# APM32F00x register map
File version: 1.0
CPU: CM0+ r0p0, little endian, no MPU, no FPU, 4 interrupt priority bits
Registers are 32-bit, read-write, reset 0x0 unless marked. A register's access mark holds for its fields unless they carry their own. Offsets are from the block's base; [hi:lo] are bit positions; {n}, {i} and the like mark numbered series.

## TMR4 — 8-bit timer
Base 0x40004000
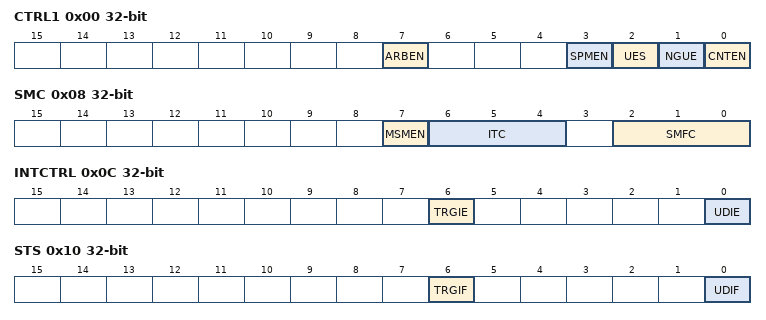
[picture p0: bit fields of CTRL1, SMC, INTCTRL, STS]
0x00 CTRL1 — control register 1
  [7] ARBEN — Auto-Reload Preload Enable mask.
  [3] SPMEN — One Pulse Mode mask.
  [2] UES — Update Request Source mask.
  [1] NGUE — Update DIsable mask.
  [0] CNTEN — Counter Enable mask.
0x04 CTRL2 — control register 2
  [6:4] MMFC — Capture/Compare Preloaded Control mask.
0x08 SMC — Synchro mode control register
  [7] MSMEN — Slave Mode Selection mask.
  [6:4] ITC — Trigger Selection mask.
  [2:0] SMFC — Master/Slave Mode mask.
0x0C INTCTRL — interrupt enable register
  [6] TRGIE — Trigger Interrupt Enable mask.
  [0] UDIE — Update Interrupt Enable mask.
0x10 STS write — status register 1
  [6] TRGIF — Trigger Interrupt Flag mask.
  [0] UDIF — Update Interrupt Flag mask.
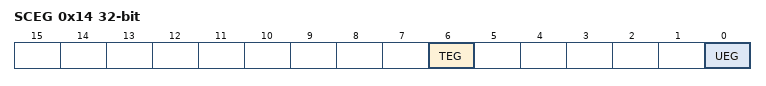
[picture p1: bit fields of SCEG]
0x14 SCEG write — event generation register
  [6] TEG — Trigger Generation mask.
  [0] UEG — Update Generation mask.
0x18 CNT — counter
  [7:0] CNT — Counter Value mask.
0x1C DIV — divider register
  [2:0] DIV — Prescaler Value mask.
0x20 AUTORLD — auto-reload register
  [7:0] RELOAD — Autoreload Value mask.

## SPI — Serial peripheral interface
Base 0x40002C00
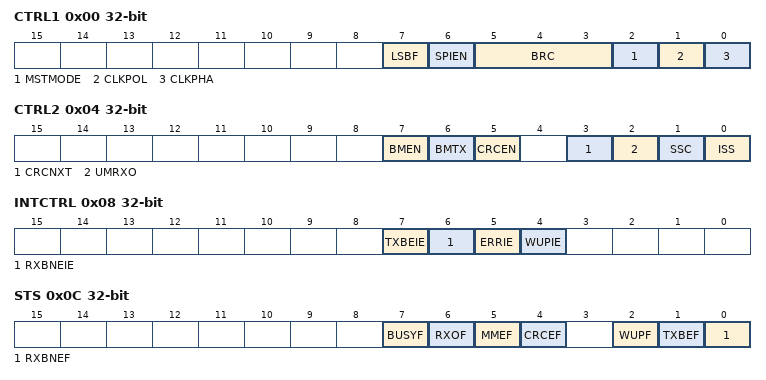
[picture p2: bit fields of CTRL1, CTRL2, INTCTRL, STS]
0x00 CTRL1 — Control register 1
  [7] LSBF, [6] SPIEN, [5:3] BRC, [2] MSTMODE, [1] CLKPOL, [0] CLKPHA
0x04 CTRL2 — Control register 2
  [7] BMEN, [6] BMTX, [5] CRCEN, [3] CRCNXT, [2] UMRXO, [1] SSC, [0] ISS
0x08 INTCTRL — Interrupt control register
  [7] TXBEIE, [6] RXBNEIE, [5] ERRIE, [4] WUPIE
0x0C STS — Status register
  [7] BUSYF, [6] RXOF, [5] MMEF, [4] CRCEF, [2] WUPF, [1] TXBEF, [0] RXBNEF
0x10 DATA
  [7:0] DATA
0x14 CRCPOLY — CRC polynomial register
  [7:0] polynomial
0x18 RXCRC ro
  [7:0] CRC
0x20 TXCRC ro
  [7:0] CRC

## ADC — Analog to digital converter
Base 0x40004400
{0x0+4i} DATABUF{i} ro (i=0..19) — Data buffer 0
  [7:0] DATABUF{i} — Regular data {i}
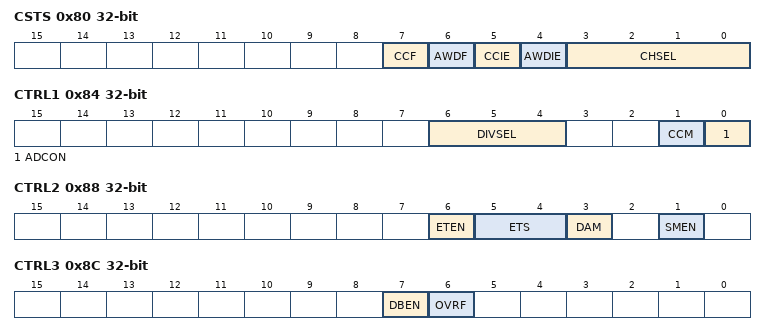
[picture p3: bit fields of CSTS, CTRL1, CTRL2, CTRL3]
0x80 CSTS — control/status register
  [7] CCF — Regular channel end of conversion
  [6] AWDF — Analog watchdog flag
  [5] CCIE
  [4] AWDIE
  [3:0] CHSEL
0x84 CTRL1 — control register 1
  [6:4] DIVSEL, [1] CCM, [0] ADCON
0x88 CTRL2 — control register 2
  [6] ETEN, [5:4] ETS, [3] DAM, [1] SMEN
0x8C CTRL3 — control register 3
  [7] DBEN, [6] OVRF
0x90 DATA1 ro — high-regular data register
  [7:0] DATA — Regular data
0x94 DATA0 ro — low-regular data register
  [7:0] DATA — Regular data
0x98 STD1 — Schmitt trigger disable register high
  [7:0] STD — Schmitt trigger prohibit high
0x9C STD0 — Schmitt trigger disable register low
  [7:0] STD — Schmitt trigger prohibit low
0xA0 AWDHT1 reset 0xFFF — watchdog higher threshold register high
  [7:0] THRESHOLD — Analog watchdog higher threshold high
0xA4 AWDHT0 reset 0x3 — watchdog higher threshold register low
  [7:0] THRESHOLD — Analog watchdog higher threshold low
0xA8 AWDLT1 — watchdog lower threshold register high
  [7:0] LT — Analog watchdog lower threshold high
0xAC AWDLT0 — watchdog lower threshold register low
  [7:0] THRESHOLD — Analog watchdog lower threshold low
0xB0 AWDS1 — Watchdog status high register
  [1:0] AWDS — Watchdog status register
0xB4 AWDS0 — Watchdog status low register
  [7:0] AWDS — Watchdog status register
0xB8 AWDEN1 — Watchdog Control high register
  [1:0] AWDEN — Watchdog Control egister
0xBC AWDEN0 — Watchdog Control low register
  [7:0] AWDEN — Watchdog Control egister
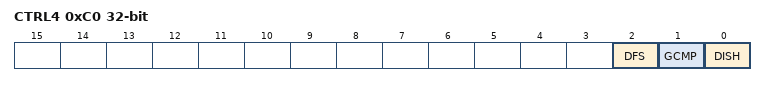
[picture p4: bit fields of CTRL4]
0xC0 CTRL4 — Control register 4
  [2] DFS, [1] GCMP, [0] DISH
0xC4 OFFSET
  [7:0] OFFSET

## EINT — External interrupt control
Base 0x40001800
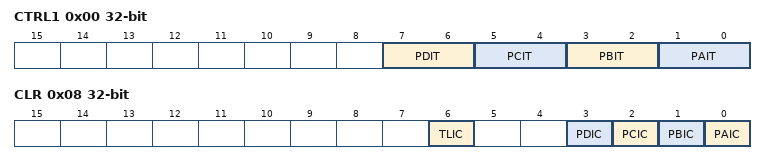
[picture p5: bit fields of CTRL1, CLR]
0x00 CTRL1 — External Interrupt Control Register for PORTA to PORTD
  [7:6] PDIT — PORTD external interrupt sensitivity bits mask
  [5:4] PCIT — PORTC external interrupt sensitivity bits mask
  [3:2] PBIT — PORTB external interrupt sensitivity bits mask
  [1:0] PAIT — PORTA external interrupt sensitivity bits mask
0x04 CTRL2 — External Interrupt Control Register for PORTE and TLI
  [2] TLIT
0x08 CLR write — External interrupt clear register
  [6] TLIC, [3] PDIC, [2] PCIC, [1] PBIC, [0] PAIC

## IWDT — Independent Watchdog
Base 0x40002000
0x00 KEYWORD wo — Key Register
  [7:0] KEY
0x04 DIV — Prescaler Register
  [2:0] DIV
0x08 CNTRLD write reset 0xFF — Reload Register
  [7:0] CNTRLD

## WWDT — Window Watchdog
Base 0x40001C00
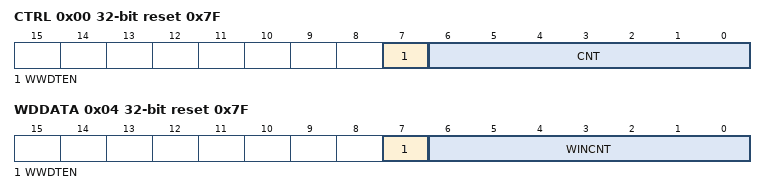
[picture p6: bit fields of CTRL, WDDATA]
0x00 CTRL reset 0x7F — Control Register
  [7] WWDTEN, [6:0] CNT
0x04 WDDATA reset 0x7F — Window Register
  [7] WWDTEN, [6:0] WINCNT

## BBEP — Beeper
Base 0x40002800
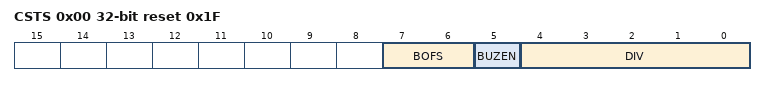
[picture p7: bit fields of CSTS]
0x00 CSTS reset 0x1F — External Interrupt Control Register for PORTA to PORTD
  [7:6] BOFS — Beeper frequency selection mask
  [5] BUZEN — Beeper enable mask
  [4:0] DIV — Beeper Divider prescalar mask

## WUPT — Auto wake up
Base 0x40002400
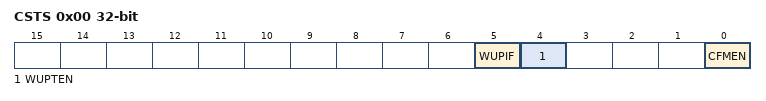
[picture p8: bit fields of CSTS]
0x00 CSTS — WUPT Control status register
  [5] WUPIF — Interrupt flag mask
  [4] WUPTEN — Auto Wake-up enable mask
  [0] CFMEN — LSI Measurement enable mask
0x04 DIV reset 0x3F — WUPT Asynchronous prescaler buffer
  [5:0] DIV — Asynchronous Prescaler divider mask
0x08 TBC write — WUPT Time base selection register
  [3:0] TBC — Timebase selection mask

## FMC — Flash Interface
Base 0x40011000
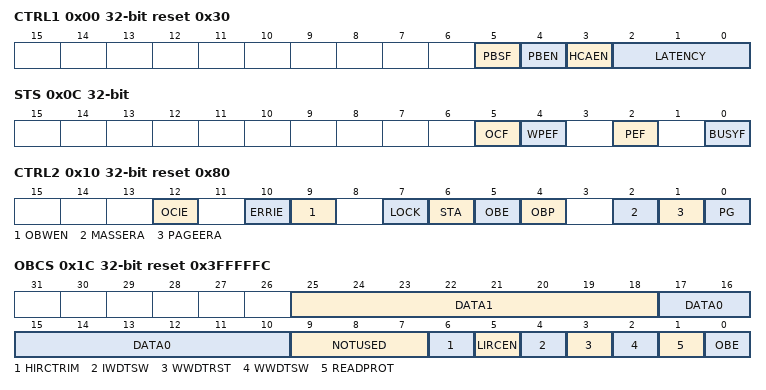
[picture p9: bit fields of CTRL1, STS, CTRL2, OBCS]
0x00 CTRL1 access per field reset 0x30 — Flash access control register
  [5] PBSF ro — Prefetch buffer status
  [4] PBEN rw — Prefetch buffer enable
  [3] HCAEN rw — Flash half cycle access enable
  [2:0] LATENCY rw
0x04 KEY wo — Flash key register
  [31:0] KEY — FPEC key
0x08 OBKEY wo — Flash option key register
  [31:0] OBEYR — Option byte key
0x0C STS access per field — Status register
  [5] OCF rw — End of operation
  [4] WPEF rw — Write protection error
  [2] PEF rw — Programming error
  [0] BUSYF ro
0x10 CTRL2 reset 0x80 — Control register
  [12] OCIE — End of operation interrupt enable
  [10] ERRIE — Error interrupt enable
  [9] OBWEN — Option bytes write enable
  [7] LOCK
  [6] STA — Start
  [5] OBE — Option byte erase
  [4] OBP — Option byte programming
  [2] MASSERA — Mass Erase
  [1] PAGEERA — Page Erase
  [0] PG — Programming
0x14 ADDR wo — Flash address register
  [31:0] ADDR — Flash Address
0x1C OBCS ro reset 0x3FFFFFC — Option byte register
  [25:18] DATA1, [17:10] DATA0, [9:7] NOTUSED, [6] HIRCTRIM, [5] LIRCEN, [4] IWDTSW, [3] WWDTRST, [2] WWDTSW, [1] READPROT, [0] OBE
0x20 WRTPROT ro reset 0xFFFFFFFF — Write protection register
  [31:0] WP — Write protect
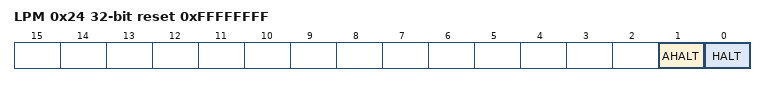
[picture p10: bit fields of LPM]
0x24 LPM reset 0xFFFFFFFF — Low power mode register
  [1] AHALT — Power-down in Halt mode
  [0] HALT — Power-down in Active-Halt mode
0x28 TPO reset 0xFFFFFFFF — tpower_on register
  [7:0] TPO

## OB — Option Bytes Registers
Base 0x00020400
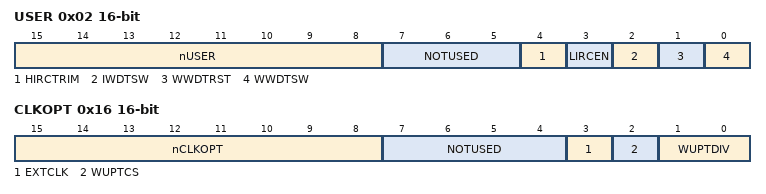
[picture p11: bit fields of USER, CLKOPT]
0x02 USER 16-bit
  [15:8] nUSER, [7:5] NOTUSED, [4] HIRCTRIM, [3] LIRCEN, [2] IWDTSW, [1] WWDTRST, [0] WWDTSW
0x04 DATA0 16-bit wo
0x06 DATA1 16-bit wo
{0x8+2i} WRTPROT{i} 16-bit (i=0..3)
0x10 AFR 16-bit
0x14 HXTCNT 16-bit
0x16 CLKOPT 16-bit
  [15:8] nCLKOPT, [7:4] NOTUSED, [3] EXTCLK, [2] WUPTCS, [1:0] WUPTDIV
